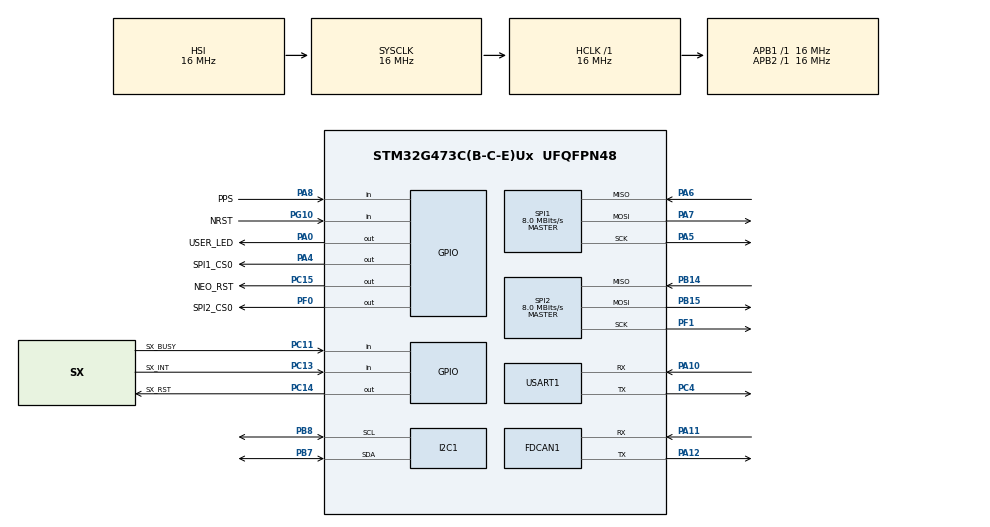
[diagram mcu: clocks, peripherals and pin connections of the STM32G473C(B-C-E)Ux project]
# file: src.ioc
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FDCAN1.CalculateBaudRateNominal=333333
FDCAN1.CalculateTimeBitNominal=3000
FDCAN1.CalculateTimeQuantumNominal=1000.0
I2C1.Timing=0x00503D58
Mcu.Family=STM32G4
Mcu.Name=STM32G473C(B-C-E)Ux
Mcu.Package=UFQFPN48
NVIC.PriorityGroup=NVIC_PRIORITYGROUP_4
PA0.GPIO_Label=USER_LED
PA0.Signal=GPIO_Output
PA10.Mode=Asynchronous
PA10.Signal=USART1_RX
PA11.Mode=FDCAN_Activate
PA11.Signal=FDCAN1_RX
PA12.Mode=FDCAN_Activate
PA12.Signal=FDCAN1_TX
PA13.Mode=Trace_Asynchronous_SW
PA13.Signal=SYS_JTMS-SWDIO
PA14.Mode=Trace_Asynchronous_SW
PA14.Signal=SYS_JTCK-SWCLK
PA4.GPIO_Label=SPI1_CS0
PA4.GPIO_Speed=GPIO_SPEED_FREQ_VERY_HIGH
PA4.Signal=GPIO_Output
PA5.Mode=Full_Duplex_Master
PA5.Signal=SPI1_SCK
PA6.Mode=Full_Duplex_Master
PA6.Signal=SPI1_MISO
PA7.Mode=Full_Duplex_Master
PA7.Signal=SPI1_MOSI
PA8.GPIO_Label=PPS
PA8.Signal=GPIO_Input
PB14.Mode=Full_Duplex_Master
PB14.Signal=SPI2_MISO
PB15.Mode=Full_Duplex_Master
PB15.Signal=SPI2_MOSI
PB3.Mode=Trace_Asynchronous_SW
PB3.Signal=SYS_JTDO-SWO
PB7.Mode=I2C
PB7.Signal=I2C1_SDA
PB8-BOOT0.Mode=I2C
PB8-BOOT0.Signal=I2C1_SCL
PC11.GPIO_Label=SX_BUSY
PC11.Signal=GPIO_Input
PC13.GPIO_Label=SX_INT
PC13.Signal=GPIO_Input
PC14-OSC32_IN.GPIO_Label=SX_RST
PC14-OSC32_IN.Signal=GPIO_Output
PC15-OSC32_OUT.GPIO_Label=NEO_RST
PC15-OSC32_OUT.Signal=GPIO_Output
PC4.Mode=Asynchronous
PC4.Signal=USART1_TX
PF0-OSC_IN.GPIO_Label=SPI2_CS0
PF0-OSC_IN.GPIO_Speed=GPIO_SPEED_FREQ_VERY_HIGH
PF0-OSC_IN.Signal=GPIO_Output
PF1-OSC_OUT.Mode=Full_Duplex_Master
PF1-OSC_OUT.Signal=SPI2_SCK
PG10-NRST.GPIO_Label=NRST
PG10-NRST.Signal=GPIO_Input
ProjectManager.HeapSize=0x200
ProjectManager.StackSize=0x400
ProjectManager.TargetToolchain=CMake
RCC.AHBFreq_Value=16000000
RCC.APB1Freq_Value=16000000
RCC.APB1TimFreq_Value=16000000
RCC.APB2Freq_Value=16000000
RCC.APB2TimFreq_Value=16000000
RCC.CortexFreq_Value=16000000
RCC.EXTERNAL_CLOCK_VALUE=12288000
RCC.HCLKFreq_Value=16000000
RCC.HSE_VALUE=8000000
RCC.HSI48_VALUE=48000000
RCC.HSI_VALUE=16000000
RCC.LSE_VALUE=32768
RCC.SYSCLKFreq_VALUE=16000000
RCC.USBFreq_Value=64000000
RCC.VCOOutputFreq_Value=128000000
SPI1.CalculateBaudRate=8.0 MBits/s
SPI1.Direction=SPI_DIRECTION_2LINES
SPI1.Mode=SPI_MODE_MASTER
SPI1.VirtualType=VM_MASTER
SPI2.CalculateBaudRate=8.0 MBits/s
SPI2.Direction=SPI_DIRECTION_2LINES
SPI2.Mode=SPI_MODE_MASTER
SPI2.VirtualType=VM_MASTER
USART1.VirtualMode-Asynchronous=VM_ASYNC
VP_SYS_VS_DBSignals.Mode=DisableDeadBatterySignals
board=custom

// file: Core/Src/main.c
/* USER CODE BEGIN Header */
/**
  ******************************************************************************
  * @file           : main.c
  * @brief          : Main program body
  ******************************************************************************
  * @attention
  *
  * Copyright (c) 2026 STMicroelectronics.
  * All rights reserved.
  *
  * This software is licensed under terms that can be found in the LICENSE file
  * in the root directory of this software component.
  * If no LICENSE file comes with this software, it is provided AS-IS.
  *
  ******************************************************************************
  */
/* USER CODE END Header */
#include "main.h"

/* USER CODE BEGIN Includes */
#include "radio/gps_driver.h"
#include "radio/lora_driver.h"
/* USER CODE END Includes */

FDCAN_HandleTypeDef hfdcan1;

I2C_HandleTypeDef hi2c1;

SPI_HandleTypeDef hspi1;
SPI_HandleTypeDef hspi2;

UART_HandleTypeDef huart1;

void SystemClock_Config(void);
static void MX_GPIO_Init(void);
static void MX_FDCAN1_Init(void);
static void MX_I2C1_Init(void);
static void MX_SPI1_Init(void);
static void MX_SPI2_Init(void);
static void MX_USART1_UART_Init(void);

int main(void)
{

  /* MCU Configuration--------------------------------------------------------*/

  /* Reset of all peripherals, Initializes the Flash interface and the Systick. */
  HAL_Init();

  /* Configure the system clock */
  SystemClock_Config();

  /* Initialize all configured peripherals */
  MX_GPIO_Init();
  MX_FDCAN1_Init();
  MX_I2C1_Init();
  MX_SPI1_Init();
  MX_SPI2_Init();
  MX_USART1_UART_Init();
  /* USER CODE BEGIN 2 */
  GPS_Init(&huart1);
  LORA_Init();
  /* USER CODE END 2 */

  /* Infinite loop */
  /* USER CODE BEGIN WHILE */
  while (1) {
    GPS_Process();
    GPS_LED_Tick();
    LORA_Process();

    if (LORA_PacketAvailable()) {
      LORA_Packet_t pkt = LORA_GetLatestPacket();
    }

    // send every 10 seconds
    if (HAL_GetTick() - LORA_GetLastSendTick() >= 10000) {
        GPS_Data_t gps = GPS_GetLatest();
        LORA_Packet_t pkt = {
            .latitude           = gps.latitude,
            .longitude          = gps.longitude,
            .altitude           = gps.altitude,
            .satellites         = gps.satellites,
            .has_fix            = gps.has_fix,
            .battery_percentage = 85,
        };
        LORA_SendPacket(&pkt);
    }
  }
}

void SystemClock_Config(void)
{
  RCC_OscInitTypeDef RCC_OscInitStruct = {0};
  RCC_ClkInitTypeDef RCC_ClkInitStruct = {0};

  /** Configure the main internal regulator output voltage
  */
  HAL_PWREx_ControlVoltageScaling(PWR_REGULATOR_VOLTAGE_SCALE1);

  /** Initializes the RCC Oscillators according to the specified parameters
  * in the RCC_OscInitTypeDef structure.
  */
  RCC_OscInitStruct.OscillatorType = RCC_OSCILLATORTYPE_HSI;
  RCC_OscInitStruct.HSIState = RCC_HSI_ON;
  RCC_OscInitStruct.HSICalibrationValue = RCC_HSICALIBRATION_DEFAULT;
  RCC_OscInitStruct.PLL.PLLState = RCC_PLL_NONE;
  if (HAL_RCC_OscConfig(&RCC_OscInitStruct) != HAL_OK)
  {
    Error_Handler();
  }

  /** Initializes the CPU, AHB and APB buses clocks
  */
  RCC_ClkInitStruct.ClockType = RCC_CLOCKTYPE_HCLK|RCC_CLOCKTYPE_SYSCLK
                              |RCC_CLOCKTYPE_PCLK1|RCC_CLOCKTYPE_PCLK2;
  RCC_ClkInitStruct.SYSCLKSource = RCC_SYSCLKSOURCE_HSI;
  RCC_ClkInitStruct.AHBCLKDivider = RCC_SYSCLK_DIV1;
  RCC_ClkInitStruct.APB1CLKDivider = RCC_HCLK_DIV1;
  RCC_ClkInitStruct.APB2CLKDivider = RCC_HCLK_DIV1;

  if (HAL_RCC_ClockConfig(&RCC_ClkInitStruct, FLASH_LATENCY_0) != HAL_OK)
  {
    Error_Handler();
  }
}

static void MX_FDCAN1_Init(void)
{

  hfdcan1.Instance = FDCAN1;
  hfdcan1.Init.ClockDivider = FDCAN_CLOCK_DIV1;
  hfdcan1.Init.FrameFormat = FDCAN_FRAME_CLASSIC;
  hfdcan1.Init.Mode = FDCAN_MODE_NORMAL;
  hfdcan1.Init.AutoRetransmission = DISABLE;
  hfdcan1.Init.TransmitPause = DISABLE;
  hfdcan1.Init.ProtocolException = DISABLE;
  hfdcan1.Init.NominalPrescaler = 16;
  hfdcan1.Init.NominalSyncJumpWidth = 1;
  hfdcan1.Init.NominalTimeSeg1 = 1;
  hfdcan1.Init.NominalTimeSeg2 = 1;
  hfdcan1.Init.DataPrescaler = 1;
  hfdcan1.Init.DataSyncJumpWidth = 1;
  hfdcan1.Init.DataTimeSeg1 = 1;
  hfdcan1.Init.DataTimeSeg2 = 1;
  hfdcan1.Init.StdFiltersNbr = 0;
  hfdcan1.Init.ExtFiltersNbr = 0;
  hfdcan1.Init.TxFifoQueueMode = FDCAN_TX_FIFO_OPERATION;
  if (HAL_FDCAN_Init(&hfdcan1) != HAL_OK)
  {
    Error_Handler();
  }

}

static void MX_I2C1_Init(void)
{

  hi2c1.Instance = I2C1;
  hi2c1.Init.Timing = 0x00503D58;
  hi2c1.Init.OwnAddress1 = 0;
  hi2c1.Init.AddressingMode = I2C_ADDRESSINGMODE_7BIT;
  hi2c1.Init.DualAddressMode = I2C_DUALADDRESS_DISABLE;
  hi2c1.Init.OwnAddress2 = 0;
  hi2c1.Init.OwnAddress2Masks = I2C_OA2_NOMASK;
  hi2c1.Init.GeneralCallMode = I2C_GENERALCALL_DISABLE;
  hi2c1.Init.NoStretchMode = I2C_NOSTRETCH_DISABLE;
  if (HAL_I2C_Init(&hi2c1) != HAL_OK)
  {
    Error_Handler();
  }

  /** Configure Analogue filter
  */
  if (HAL_I2CEx_ConfigAnalogFilter(&hi2c1, I2C_ANALOGFILTER_ENABLE) != HAL_OK)
  {
    Error_Handler();
  }

  /** Configure Digital filter
  */
  if (HAL_I2CEx_ConfigDigitalFilter(&hi2c1, 0) != HAL_OK)
  {
    Error_Handler();
  }

}

static void MX_SPI1_Init(void)
{

  /* SPI1 parameter configuration*/
  hspi1.Instance = SPI1;
  hspi1.Init.Mode = SPI_MODE_MASTER;
  hspi1.Init.Direction = SPI_DIRECTION_2LINES;
  hspi1.Init.DataSize = SPI_DATASIZE_4BIT;
  hspi1.Init.CLKPolarity = SPI_POLARITY_LOW;
  hspi1.Init.CLKPhase = SPI_PHASE_1EDGE;
  hspi1.Init.NSS = SPI_NSS_SOFT;
  hspi1.Init.BaudRatePrescaler = SPI_BAUDRATEPRESCALER_2;
  hspi1.Init.FirstBit = SPI_FIRSTBIT_MSB;
  hspi1.Init.TIMode = SPI_TIMODE_DISABLE;
  hspi1.Init.CRCCalculation = SPI_CRCCALCULATION_DISABLE;
  hspi1.Init.CRCPolynomial = 7;
  hspi1.Init.CRCLength = SPI_CRC_LENGTH_DATASIZE;
  hspi1.Init.NSSPMode = SPI_NSS_PULSE_ENABLE;
  if (HAL_SPI_Init(&hspi1) != HAL_OK)
  {
    Error_Handler();
  }

}

static void MX_SPI2_Init(void)
{

  /* SPI2 parameter configuration*/
  hspi2.Instance = SPI2;
  hspi2.Init.Mode = SPI_MODE_MASTER;
  hspi2.Init.Direction = SPI_DIRECTION_2LINES;
  hspi2.Init.DataSize = SPI_DATASIZE_4BIT;
  hspi2.Init.CLKPolarity = SPI_POLARITY_LOW;
  hspi2.Init.CLKPhase = SPI_PHASE_1EDGE;
  hspi2.Init.NSS = SPI_NSS_SOFT;
  hspi2.Init.BaudRatePrescaler = SPI_BAUDRATEPRESCALER_2;
  hspi2.Init.FirstBit = SPI_FIRSTBIT_MSB;
  hspi2.Init.TIMode = SPI_TIMODE_DISABLE;
  hspi2.Init.CRCCalculation = SPI_CRCCALCULATION_DISABLE;
  hspi2.Init.CRCPolynomial = 7;
  hspi2.Init.CRCLength = SPI_CRC_LENGTH_DATASIZE;
  hspi2.Init.NSSPMode = SPI_NSS_PULSE_ENABLE;
  if (HAL_SPI_Init(&hspi2) != HAL_OK)
  {
    Error_Handler();
  }

}

static void MX_USART1_UART_Init(void)
{

  huart1.Instance = USART1;
  huart1.Init.BaudRate = 115200;
  huart1.Init.WordLength = UART_WORDLENGTH_8B;
  huart1.Init.StopBits = UART_STOPBITS_1;
  huart1.Init.Parity = UART_PARITY_NONE;
  huart1.Init.Mode = UART_MODE_TX_RX;
  huart1.Init.HwFlowCtl = UART_HWCONTROL_NONE;
  huart1.Init.OverSampling = UART_OVERSAMPLING_16;
  huart1.Init.OneBitSampling = UART_ONE_BIT_SAMPLE_DISABLE;
  huart1.Init.ClockPrescaler = UART_PRESCALER_DIV1;
  huart1.AdvancedInit.AdvFeatureInit = UART_ADVFEATURE_NO_INIT;
  if (HAL_UART_Init(&huart1) != HAL_OK)
  {
    Error_Handler();
  }
  if (HAL_UARTEx_SetTxFifoThreshold(&huart1, UART_TXFIFO_THRESHOLD_1_8) != HAL_OK)
  {
    Error_Handler();
  }
  if (HAL_UARTEx_SetRxFifoThreshold(&huart1, UART_RXFIFO_THRESHOLD_1_8) != HAL_OK)
  {
    Error_Handler();
  }
  if (HAL_UARTEx_DisableFifoMode(&huart1) != HAL_OK)
  {
    Error_Handler();
  }

}

static void MX_GPIO_Init(void)
{
  GPIO_InitTypeDef GPIO_InitStruct = {0};

  /* GPIO Ports Clock Enable */
  __HAL_RCC_GPIOC_CLK_ENABLE();
  __HAL_RCC_GPIOF_CLK_ENABLE();
  __HAL_RCC_GPIOG_CLK_ENABLE();
  __HAL_RCC_GPIOA_CLK_ENABLE();
  __HAL_RCC_GPIOB_CLK_ENABLE();

  /*Configure GPIO pin Output Level */
  HAL_GPIO_WritePin(GPIOC, SX_RST_Pin|NEO_RST_Pin, GPIO_PIN_RESET);

  /*Configure GPIO pin Output Level */
  HAL_GPIO_WritePin(SPI2_CS0_GPIO_Port, SPI2_CS0_Pin, GPIO_PIN_RESET);

  /*Configure GPIO pin Output Level */
  HAL_GPIO_WritePin(GPIOA, USER_LED_Pin|SPI1_CS0_Pin, GPIO_PIN_RESET);

  /*Configure GPIO pins : SX_INT_Pin SX_BUSY_Pin */
  GPIO_InitStruct.Pin = SX_INT_Pin|SX_BUSY_Pin;
  GPIO_InitStruct.Mode = GPIO_MODE_INPUT;
  GPIO_InitStruct.Pull = GPIO_NOPULL;
  HAL_GPIO_Init(GPIOC, &GPIO_InitStruct);

  /*Configure GPIO pins : SX_RST_Pin NEO_RST_Pin */
  GPIO_InitStruct.Pin = SX_RST_Pin|NEO_RST_Pin;
  GPIO_InitStruct.Mode = GPIO_MODE_OUTPUT_PP;
  GPIO_InitStruct.Pull = GPIO_NOPULL;
  GPIO_InitStruct.Speed = GPIO_SPEED_FREQ_LOW;
  HAL_GPIO_Init(GPIOC, &GPIO_InitStruct);

  /*Configure GPIO pin : SPI2_CS0_Pin */
  GPIO_InitStruct.Pin = SPI2_CS0_Pin;
  GPIO_InitStruct.Mode = GPIO_MODE_OUTPUT_PP;
  GPIO_InitStruct.Pull = GPIO_NOPULL;
  GPIO_InitStruct.Speed = GPIO_SPEED_FREQ_VERY_HIGH;
  HAL_GPIO_Init(SPI2_CS0_GPIO_Port, &GPIO_InitStruct);

  /*Configure GPIO pin : NRST_Pin */
  GPIO_InitStruct.Pin = NRST_Pin;
  GPIO_InitStruct.Mode = GPIO_MODE_INPUT;
  GPIO_InitStruct.Pull = GPIO_NOPULL;
  HAL_GPIO_Init(NRST_GPIO_Port, &GPIO_InitStruct);

  /*Configure GPIO pin : USER_LED_Pin */
  GPIO_InitStruct.Pin = USER_LED_Pin;
  GPIO_InitStruct.Mode = GPIO_MODE_OUTPUT_PP;
  GPIO_InitStruct.Pull = GPIO_NOPULL;
  GPIO_InitStruct.Speed = GPIO_SPEED_FREQ_LOW;
  HAL_GPIO_Init(USER_LED_GPIO_Port, &GPIO_InitStruct);

  /*Configure GPIO pin : SPI1_CS0_Pin */
  GPIO_InitStruct.Pin = SPI1_CS0_Pin;
  GPIO_InitStruct.Mode = GPIO_MODE_OUTPUT_PP;
  GPIO_InitStruct.Pull = GPIO_NOPULL;
  GPIO_InitStruct.Speed = GPIO_SPEED_FREQ_VERY_HIGH;
  HAL_GPIO_Init(SPI1_CS0_GPIO_Port, &GPIO_InitStruct);

  /*Configure GPIO pin : PPS_Pin */
  GPIO_InitStruct.Pin = PPS_Pin;
  GPIO_InitStruct.Mode = GPIO_MODE_INPUT;
  GPIO_InitStruct.Pull = GPIO_NOPULL;
  HAL_GPIO_Init(PPS_GPIO_Port, &GPIO_InitStruct);

}

void Error_Handler(void)
{
  __disable_irq();
  while (1)
  {
  }
}
